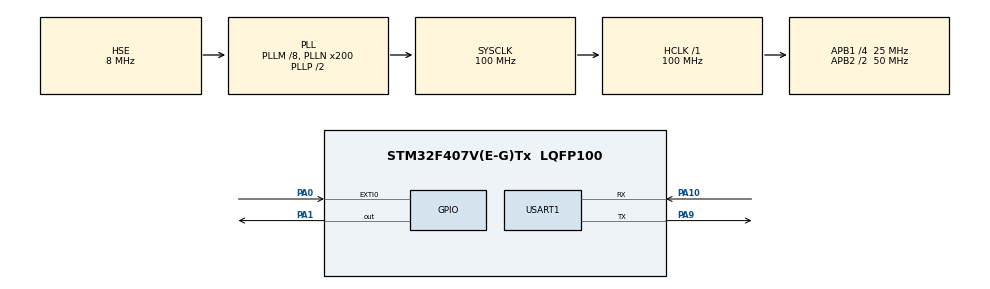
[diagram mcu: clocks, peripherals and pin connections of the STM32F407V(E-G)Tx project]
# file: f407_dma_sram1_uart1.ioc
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Dma.Request0=USART1_TX
Dma.USART1_TX.0.Direction=DMA_MEMORY_TO_PERIPH
Dma.USART1_TX.0.FIFOMode=DMA_FIFOMODE_ENABLE
Dma.USART1_TX.0.FIFOThreshold=DMA_FIFO_THRESHOLD_FULL
Dma.USART1_TX.0.Instance=DMA2_Stream7
Dma.USART1_TX.0.MemBurst=DMA_MBURST_SINGLE
Dma.USART1_TX.0.MemDataAlignment=DMA_MDATAALIGN_BYTE
Dma.USART1_TX.0.MemInc=DMA_MINC_ENABLE
Dma.USART1_TX.0.Mode=DMA_NORMAL
Dma.USART1_TX.0.PeriphBurst=DMA_PBURST_SINGLE
Dma.USART1_TX.0.PeriphDataAlignment=DMA_PDATAALIGN_BYTE
Dma.USART1_TX.0.PeriphInc=DMA_PINC_DISABLE
Dma.USART1_TX.0.Priority=DMA_PRIORITY_LOW
Mcu.Family=STM32F4
Mcu.Name=STM32F407V(E-G)Tx
Mcu.Package=LQFP100
NVIC.DMA2_Stream7_IRQn=true\:0\:0\:false\:false\:true\:false\:true
NVIC.EXTI0_IRQn=true\:0\:0\:false\:false\:true\:true\:true
NVIC.PriorityGroup=NVIC_PRIORITYGROUP_4
NVIC.USART1_IRQn=true\:0\:0\:false\:false\:true\:true\:true
PA0-WKUP.GPIO_PuPd=GPIO_PULLDOWN
PA0-WKUP.Signal=GPXTI0
PA1.Signal=GPIO_Output
PA10.Mode=Asynchronous
PA10.Signal=USART1_RX
PA13.Mode=Serial_Wire
PA13.Signal=SYS_JTMS-SWDIO
PA14.Mode=Serial_Wire
PA14.Signal=SYS_JTCK-SWCLK
PA9.Mode=Asynchronous
PA9.Signal=USART1_TX
PH0-OSC_IN.Mode=HSE-External-Oscillator
PH0-OSC_IN.Signal=RCC_OSC_IN
PH1-OSC_OUT.Mode=HSE-External-Oscillator
PH1-OSC_OUT.Signal=RCC_OSC_OUT
ProjectManager.HeapSize=0x200
ProjectManager.StackSize=0x400
ProjectManager.TargetToolchain=STM32CubeIDE
RCC.48MHZClocksFreq_Value=50000000
RCC.AHBFreq_Value=100000000
RCC.APB1CLKDivider=RCC_HCLK_DIV4
RCC.APB1Freq_Value=25000000
RCC.APB1TimFreq_Value=50000000
RCC.APB2CLKDivider=RCC_HCLK_DIV2
RCC.APB2Freq_Value=50000000
RCC.APB2TimFreq_Value=100000000
RCC.CortexFreq_Value=100000000
RCC.HCLKFreq_Value=100000000
RCC.HSE_VALUE=8000000
RCC.HSI_VALUE=16000000
RCC.LSE_VALUE=32768
RCC.PLLM=8
RCC.PLLN=200
RCC.PLLSourceVirtual=RCC_PLLSOURCE_HSE
RCC.SYSCLKFreq_VALUE=100000000
RCC.SYSCLKSource=RCC_SYSCLKSOURCE_PLLCLK
RCC.VCOOutputFreq_Value=200000000
USART1.VirtualMode=VM_ASYNC
board=custom

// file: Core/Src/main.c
/* USER CODE BEGIN Header */
// DevEBox STM32F407VGT6 dev board
// Demo DMA transfer of data from SRAM1 to UART1 (memory to peripheral transfer)
// DMA configured in FIFO mode with threshold FULL. In this case the DMA engine
// preloads the 4byte FIFO with 4bytes of data from SRAM1 source, and drains it
// when the UART1 peripheral issues a request.
// The DMA controller will reload the FIFO with more data from SRAM1 whenever
// the FIFO level goes below FULL.
// Note : CubeMX config of UART1 and DMA2 does not enable USART1 global interrupt
// but without enabling the interrupt, it will not work after first transmit. You
// will get an error HAL_BUSY if you call the Transmit_DMA function again.
// The HAL api uses the TX complete interrupt callback to reset HAL status flags.

// Data transfer is initiated by pressing the button K1 connecting PA0 to VCC.

/* USER CODE END Header */

#include "main.h"

UART_HandleTypeDef huart1;
DMA_HandleTypeDef hdma_usart1_tx;

void SystemClock_Config(void);
static void MX_GPIO_Init(void);
static void MX_DMA_Init(void);
static void MX_USART1_UART_Init(void);
/* USER CODE BEGIN PFP */
void dmaCompleteCallback(DMA_HandleTypeDef* hdma);
HAL_StatusTypeDef HAL_UART_DMA_Tx_Stop(UART_HandleTypeDef *huart);
/* USER CODE END PFP */

/* USER CODE BEGIN 0 */

// data source for DMA transfer is in SRAM1
char dataSource[] = "The quick brown fox jumps over the lazy dog\r\n";
/* USER CODE END 0 */

int main(void)
{

  /* MCU Configuration--------------------------------------------------------*/

  /* Reset of all peripherals, Initializes the Flash interface and the Systick. */
  HAL_Init();

  /* Configure the system clock */
  SystemClock_Config();

  /* Initialize all configured peripherals */
  MX_GPIO_Init();
  MX_DMA_Init();
  MX_USART1_UART_Init();

  /* Infinite loop */
  while (1)
  {

  }
}

void SystemClock_Config(void)
{
  RCC_OscInitTypeDef RCC_OscInitStruct = {0};
  RCC_ClkInitTypeDef RCC_ClkInitStruct = {0};

  /** Configure the main internal regulator output voltage
  */
  __HAL_RCC_PWR_CLK_ENABLE();
  __HAL_PWR_VOLTAGESCALING_CONFIG(PWR_REGULATOR_VOLTAGE_SCALE1);
  /** Initializes the CPU, AHB and APB busses clocks
  */
  RCC_OscInitStruct.OscillatorType = RCC_OSCILLATORTYPE_HSE;
  RCC_OscInitStruct.HSEState = RCC_HSE_ON;
  RCC_OscInitStruct.PLL.PLLState = RCC_PLL_ON;
  RCC_OscInitStruct.PLL.PLLSource = RCC_PLLSOURCE_HSE;
  RCC_OscInitStruct.PLL.PLLM = 8;
  RCC_OscInitStruct.PLL.PLLN = 200;
  RCC_OscInitStruct.PLL.PLLP = RCC_PLLP_DIV2;
  RCC_OscInitStruct.PLL.PLLQ = 4;
  if (HAL_RCC_OscConfig(&RCC_OscInitStruct) != HAL_OK)
  {
    Error_Handler();
  }
  /** Initializes the CPU, AHB and APB busses clocks
  */
  RCC_ClkInitStruct.ClockType = RCC_CLOCKTYPE_HCLK|RCC_CLOCKTYPE_SYSCLK
                              |RCC_CLOCKTYPE_PCLK1|RCC_CLOCKTYPE_PCLK2;
  RCC_ClkInitStruct.SYSCLKSource = RCC_SYSCLKSOURCE_PLLCLK;
  RCC_ClkInitStruct.AHBCLKDivider = RCC_SYSCLK_DIV1;
  RCC_ClkInitStruct.APB1CLKDivider = RCC_HCLK_DIV4;
  RCC_ClkInitStruct.APB2CLKDivider = RCC_HCLK_DIV2;

  if (HAL_RCC_ClockConfig(&RCC_ClkInitStruct, FLASH_LATENCY_3) != HAL_OK)
  {
    Error_Handler();
  }
}

static void MX_USART1_UART_Init(void)
{

  huart1.Instance = USART1;
  huart1.Init.BaudRate = 115200;
  huart1.Init.WordLength = UART_WORDLENGTH_8B;
  huart1.Init.StopBits = UART_STOPBITS_1;
  huart1.Init.Parity = UART_PARITY_NONE;
  huart1.Init.Mode = UART_MODE_TX_RX;
  huart1.Init.HwFlowCtl = UART_HWCONTROL_NONE;
  huart1.Init.OverSampling = UART_OVERSAMPLING_16;
  if (HAL_UART_Init(&huart1) != HAL_OK)
  {
    Error_Handler();
  }

}

static void MX_DMA_Init(void)
{

  /* DMA controller clock enable */
  __HAL_RCC_DMA2_CLK_ENABLE();

  /* DMA interrupt init */
  /* DMA2_Stream7_IRQn interrupt configuration */
  HAL_NVIC_SetPriority(DMA2_Stream7_IRQn, 0, 0);
  HAL_NVIC_EnableIRQ(DMA2_Stream7_IRQn);

}

static void MX_GPIO_Init(void)
{
  GPIO_InitTypeDef GPIO_InitStruct = {0};

  /* GPIO Ports Clock Enable */
  __HAL_RCC_GPIOH_CLK_ENABLE();
  __HAL_RCC_GPIOA_CLK_ENABLE();

  /*Configure GPIO pin Output Level */
  HAL_GPIO_WritePin(GPIOA, GPIO_PIN_1, GPIO_PIN_RESET);

  /*Configure GPIO pin : PA0 */
  GPIO_InitStruct.Pin = GPIO_PIN_0;
  GPIO_InitStruct.Mode = GPIO_MODE_IT_RISING;
  GPIO_InitStruct.Pull = GPIO_PULLDOWN;
  HAL_GPIO_Init(GPIOA, &GPIO_InitStruct);

  /*Configure GPIO pin : PA1 */
  GPIO_InitStruct.Pin = GPIO_PIN_1;
  GPIO_InitStruct.Mode = GPIO_MODE_OUTPUT_PP;
  GPIO_InitStruct.Pull = GPIO_NOPULL;
  GPIO_InitStruct.Speed = GPIO_SPEED_FREQ_LOW;
  HAL_GPIO_Init(GPIOA, &GPIO_InitStruct);

  /* EXTI interrupt init*/
  HAL_NVIC_SetPriority(EXTI0_IRQn, 0, 0);
  HAL_NVIC_EnableIRQ(EXTI0_IRQn);

}

/* USER CODE BEGIN 4 */

// callback from EXTI0 IRQ Handler when we press K1 button
void HAL_GPIO_EXTI_Callback(uint16_t gpioPin) {
	// send uart  transmit request to DMA2 controller
	if (HAL_OK !=  HAL_UART_Transmit_DMA(&huart1, (uint8_t*) dataSource, (uint16_t)sizeof(dataSource))) {
		Error_Handler();
		}
	}

// indicate DMA transfer complete by toggling board led at PA1
void HAL_UART_TxCpltCallback(UART_HandleTypeDef *huart){
	HAL_GPIO_TogglePin(GPIOA, GPIO_PIN_1);
	}

/* USER CODE END 4 */

void Error_Handler(void)
{
  /* USER CODE BEGIN Error_Handler_Debug */
  /* User can add his own implementation to report the HAL error return state */
	// toggle the board LED rapidly
	int counter = 0;
	while (1) {
		HAL_GPIO_TogglePin(GPIOA, GPIO_PIN_1);
		while (counter < 0x3FFFF) {counter++;}
		counter = 0;
		}
  /* USER CODE END Error_Handler_Debug */
}

/************************ (C) COPYRIGHT STMicroelectronics *****END OF FILE****/
